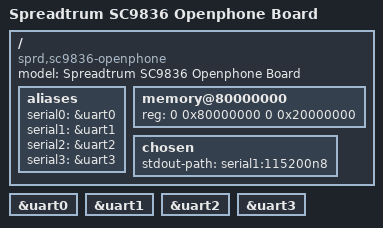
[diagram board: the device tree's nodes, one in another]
// SPDX-License-Identifier: (GPL-2.0-only OR MIT)
/*
 * Spreadtrum SC9836 openphone board DTS file
 *
 * Copyright (C) 2014, Spreadtrum Communications Inc.
 */

/dts-v1/;

#include "sc9836.dtsi"

/ {
	model = "Spreadtrum SC9836 Openphone Board";

	compatible = "sprd,sc9836-openphone", "sprd,sc9836";

	aliases {
		serial0 = &uart0;
		serial1 = &uart1;
		serial2 = &uart2;
		serial3 = &uart3;
	};

	memory@80000000 {
		device_type = "memory";
		reg = <0 0x80000000 0 0x20000000>;
	};

	chosen {
		stdout-path = "serial1:115200n8";
	};
};

&uart0 {
	status = "okay";
};

&uart1 {
	status = "okay";
};

&uart2 {
	status = "okay";
};

&uart3 {
	status = "okay";
};
